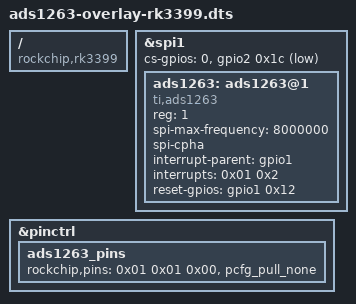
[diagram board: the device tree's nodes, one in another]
/*
 * Device tree overlay for ads1263 on spi1.1
 */

/dts-v1/;
/plugin/;

/ {
    compatible = "rockchip,rk3399";

    /* https://forum.armbian.com/topic/12227-httpsforumarmbiancomtopic12227-rockpi-4-spirockpi-4-spi/page/2/ */
    fragment@0 {
        target = <&spi1>;
        __overlay__ {
            status = "okay";
            cs-gpios = <0>, <&gpio2 0x1c 1>;
        };
    };

    /* the drdy pin */
    fragment@1 {
        target = <&pinctrl>;
        __overlay__ {
            ads1263_pins: ads1263_pins {
                rockchip,pins = <0x01 0x01 0x00 &pcfg_pull_none>; /* GPIO1_A1 */
            };
        };
    };

    fragment@2 {
        target = <&spi1>;
        __overlay__ {
            /* needed to avoid dtc warning */
            #address-cells = <1>;
            #size-cells = <0>;
            ads1263: ads1263@1 {
                compatible = "ti,ads1263";
                reg = <1>;
                spi-max-frequency = <8000000>;
                spi-cpha;
                
                interrupt-parent = <&gpio1>;
                interrupts = <0x01 0x2>;

                reset-gpios = <&gpio1 0x12 0>;
            };
        };
    };

    __overrides__ {
        spimaxfrequency = <&ads1263>,"spi-max-frequency:0";
        interrupt = <&ads1263_pins>,"brcm,pins:0",<&ads1263>,"interrupts:0";
    };
};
